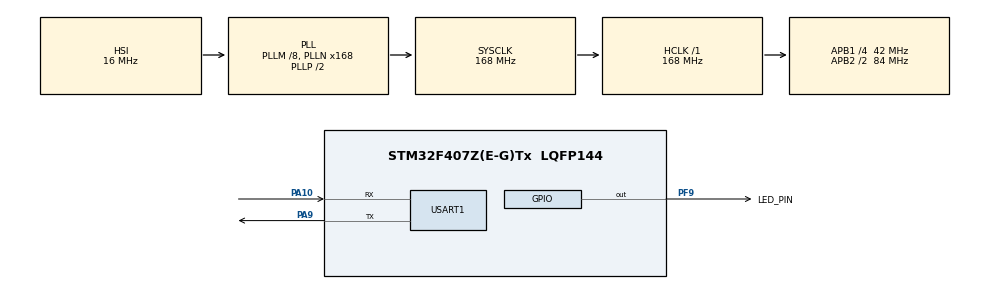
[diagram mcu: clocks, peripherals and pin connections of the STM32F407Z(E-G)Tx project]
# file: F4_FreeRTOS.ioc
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FREERTOS.Mutexes01=myMutex01,Dynamic,NULL,Available
FREERTOS.Tasks01=LCDTask,24,128,StartLCDTask,Default,NULL,Dynamic,NULL,NULL;USARTTask,32,128,StartUSARTTask,Default,NULL,Dynamic,NULL,NULL
Mcu.Family=STM32F4
Mcu.Name=STM32F407Z(E-G)Tx
Mcu.Package=LQFP144
NVIC.PriorityGroup=NVIC_PRIORITYGROUP_4
NVIC.TIM6_DAC_IRQn=true\:15\:0\:false\:false\:true\:false\:false\:true\:true
NVIC.TimeBase=TIM6_DAC_IRQn
NVIC.TimeBaseIP=TIM6
NVIC.USART1_IRQn=true\:5\:0\:false\:false\:true\:true\:true\:true\:true
PA10.Mode=Asynchronous
PA10.Signal=USART1_RX
PA13.Mode=Serial_Wire
PA13.Signal=SYS_JTMS-SWDIO
PA14.Mode=Serial_Wire
PA14.Signal=SYS_JTCK-SWCLK
PA9.Mode=Asynchronous
PA9.Signal=USART1_TX
PF9.GPIO_Label=LED_PIN
PF9.Signal=GPIO_Output
PH0-OSC_IN.Mode=HSE-External-Oscillator
PH0-OSC_IN.Signal=RCC_OSC_IN
PH1-OSC_OUT.Mode=HSE-External-Oscillator
PH1-OSC_OUT.Signal=RCC_OSC_OUT
ProjectManager.HeapSize=0x400
ProjectManager.StackSize=0x1000
ProjectManager.TargetToolchain=CMake
RCC.48MHZClocksFreq_Value=84000000
RCC.AHBFreq_Value=168000000
RCC.APB1CLKDivider=RCC_HCLK_DIV4
RCC.APB1Freq_Value=42000000
RCC.APB1TimFreq_Value=84000000
RCC.APB2CLKDivider=RCC_HCLK_DIV2
RCC.APB2Freq_Value=84000000
RCC.APB2TimFreq_Value=168000000
RCC.CortexFreq_Value=168000000
RCC.HCLKFreq_Value=168000000
RCC.HSE_VALUE=8000000
RCC.HSI_VALUE=16000000
RCC.LSE_VALUE=32768
RCC.PLLM=8
RCC.PLLN=168
RCC.SYSCLKFreq_VALUE=168000000
RCC.SYSCLKSource=RCC_SYSCLKSOURCE_PLLCLK
RCC.VCOOutputFreq_Value=336000000
USART1.VirtualMode=VM_ASYNC
VP_FREERTOS_VS_CMSIS_V2.Mode=CMSIS_V2
VP_SYS_VS_tim6.Mode=TIM6
board=custom

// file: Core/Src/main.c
/* USER CODE BEGIN Header */
/**
  ******************************************************************************
  * @file           : main.c
  * @brief          : Main program body
  ******************************************************************************
  * @attention
  *
  * Copyright (c) 2026 STMicroelectronics.
  * All rights reserved.
  *
  * This software is licensed under terms that can be found in the LICENSE file
  * in the root directory of this software component.
  * If no LICENSE file comes with this software, it is provided AS-IS.
  *
  ******************************************************************************
  */
/* USER CODE END Header */
#include "main.h"
#include "cmsis_os.h"
#include "usart.h"
#include "gpio.h"

void SystemClock_Config(void);
void MX_FREERTOS_Init(void);

int main(void)
{

  /* MCU Configuration--------------------------------------------------------*/

  /* Reset of all peripherals, Initializes the Flash interface and the Systick. */
  HAL_Init();

  /* Configure the system clock */
  SystemClock_Config();

  /* Initialize all configured peripherals */
  MX_GPIO_Init();
  MX_USART1_UART_Init();

  /* Init scheduler */
  osKernelInitialize();  /* Call init function for freertos objects (in cmsis_os2.c) */
  MX_FREERTOS_Init();

  /* Start scheduler */
  osKernelStart();

  /* We should never get here as control is now taken by the scheduler */

  /* Infinite loop */
  while (1)
  {

  }
}

void SystemClock_Config(void)
{
  RCC_OscInitTypeDef RCC_OscInitStruct = {0};
  RCC_ClkInitTypeDef RCC_ClkInitStruct = {0};

  /** Configure the main internal regulator output voltage
  */
  __HAL_RCC_PWR_CLK_ENABLE();
  __HAL_PWR_VOLTAGESCALING_CONFIG(PWR_REGULATOR_VOLTAGE_SCALE1);

  /** Initializes the RCC Oscillators according to the specified parameters
  * in the RCC_OscInitTypeDef structure.
  */
  RCC_OscInitStruct.OscillatorType = RCC_OSCILLATORTYPE_HSI;
  RCC_OscInitStruct.HSIState = RCC_HSI_ON;
  RCC_OscInitStruct.HSICalibrationValue = RCC_HSICALIBRATION_DEFAULT;
  RCC_OscInitStruct.PLL.PLLState = RCC_PLL_ON;
  RCC_OscInitStruct.PLL.PLLSource = RCC_PLLSOURCE_HSI;
  RCC_OscInitStruct.PLL.PLLM = 8;
  RCC_OscInitStruct.PLL.PLLN = 168;
  RCC_OscInitStruct.PLL.PLLP = RCC_PLLP_DIV2;
  RCC_OscInitStruct.PLL.PLLQ = 4;
  if (HAL_RCC_OscConfig(&RCC_OscInitStruct) != HAL_OK)
  {
    Error_Handler();
  }

  /** Initializes the CPU, AHB and APB buses clocks
  */
  RCC_ClkInitStruct.ClockType = RCC_CLOCKTYPE_HCLK|RCC_CLOCKTYPE_SYSCLK
                              |RCC_CLOCKTYPE_PCLK1|RCC_CLOCKTYPE_PCLK2;
  RCC_ClkInitStruct.SYSCLKSource = RCC_SYSCLKSOURCE_PLLCLK;
  RCC_ClkInitStruct.AHBCLKDivider = RCC_SYSCLK_DIV1;
  RCC_ClkInitStruct.APB1CLKDivider = RCC_HCLK_DIV4;
  RCC_ClkInitStruct.APB2CLKDivider = RCC_HCLK_DIV2;

  if (HAL_RCC_ClockConfig(&RCC_ClkInitStruct, FLASH_LATENCY_5) != HAL_OK)
  {
    Error_Handler();
  }
}

void HAL_TIM_PeriodElapsedCallback(TIM_HandleTypeDef *htim)
{
  if (htim->Instance == TIM6)
  {
    HAL_IncTick();
  }
}

void Error_Handler(void)
{
  __disable_irq();
  while (1)
  {
  }
}

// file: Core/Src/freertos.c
/* USER CODE BEGIN Header */
/**
 ******************************************************************************
 * File Name          : freertos.c
 * Description        : Code for freertos applications
 ******************************************************************************
 * @attention
 *
 * Copyright (c) 2026 STMicroelectronics.
 * All rights reserved.
 *
 * This software is licensed under terms that can be found in the LICENSE file
 * in the root directory of this software component.
 * If no LICENSE file comes with this software, it is provided AS-IS.
 *
 ******************************************************************************
 */
/* USER CODE END Header */

#include "FreeRTOS.h"
#include "task.h"
#include "main.h"
#include "cmsis_os.h"

/* USER CODE BEGIN Includes */
#include "gpio.h"
#include "stdarg.h"
#include "stdio.h"
#include "string.h"
#include "usart.h"
/* USER CODE END Includes */

/* USER CODE BEGIN PD */
#define LED_TOGGLE_PERIOD       100  // 100ms (0.1秒)
#define USART_BUFFER_SIZE       64
#define HELLO_WORLD_INTERVAL    500  // 500ms发送一次hello world
/* USER CODE END PD */

/* USER CODE BEGIN Variables */
volatile uint8_t led_state = 0;

/* USER CODE END Variables */
/* Definitions for LCDTask */
osThreadId_t LCDTaskHandle;
const osThreadAttr_t LCDTask_attributes = {
  .name = "LCDTask",
  .stack_size = 128 * 4,
  .priority = (osPriority_t) osPriorityNormal,
};
/* Definitions for USARTTask */
osThreadId_t USARTTaskHandle;
const osThreadAttr_t USARTTask_attributes = {
  .name = "USARTTask",
  .stack_size = 128 * 4,
  .priority = (osPriority_t) osPriorityAboveNormal,
};
/* Definitions for myMutex01 */
osMutexId_t myMutex01Handle;
const osMutexAttr_t myMutex01_attributes = {
  .name = "myMutex01"
};

void StartLCDTask(void *argument);
void StartUSARTTask(void *argument);

void MX_FREERTOS_Init(void); /* (MISRA C 2004 rule 8.1) */

void MX_FREERTOS_Init(void) {
  /* Create the mutex(es) */
  /* creation of myMutex01 */
  myMutex01Handle = osMutexNew(&myMutex01_attributes);

  /* Create the thread(s) */
  /* creation of LCDTask */
  LCDTaskHandle = osThreadNew(StartLCDTask, NULL, &LCDTask_attributes);

  /* creation of USARTTask */
  USARTTaskHandle = osThreadNew(StartUSARTTask, NULL, &USARTTask_attributes);

}

void StartLCDTask(void *argument)
{
  /* USER CODE BEGIN StartLCDTask */
  uint32_t last_toggle_time = 0;
  uint32_t current_time = 0;

  // 使用互斥锁保护UART访问
  if (osMutexAcquire(myMutex01Handle, osWaitForever) == osOK) {
    HAL_UART_Transmit(&huart1, (uint8_t*)"LED Control Task Started\r\n", 26, HAL_MAX_DELAY);
    osMutexRelease(myMutex01Handle);
  }

  /* Infinite loop */
  for(;;)
  {
    current_time = HAL_GetTick();

    // 0.1秒自动闪烁
    if (current_time - last_toggle_time >= LED_TOGGLE_PERIOD) {
      HAL_GPIO_TogglePin(LED_PIN_GPIO_Port, LED_PIN_Pin);
      led_state = !led_state;
      last_toggle_time = current_time;

      // 安全的UART打印
      if (osMutexAcquire(myMutex01Handle, osWaitForever) == osOK) {
        char msg[30];
        snprintf(msg, sizeof(msg), "LED Toggled - State: %d\r\n", led_state);
        HAL_UART_Transmit(&huart1, (uint8_t*)msg, strlen(msg), HAL_MAX_DELAY);
        osMutexRelease(myMutex01Handle);
      }
    }

    osDelay(10); // 10ms延迟，降低CPU占用
  }
  /* USER CODE END StartLCDTask */
}

void StartUSARTTask(void *argument)
{
  /* USER CODE BEGIN StartUSARTTask */
  uint32_t last_hello_time = 0;
  uint32_t current_time = 0;

  // 使用互斥锁保护初始化消息
  if (osMutexAcquire(myMutex01Handle, osWaitForever) == osOK) {
    HAL_UART_Transmit(&huart1, (uint8_t*)"USART Communication Task Started!\r\n", 35, HAL_MAX_DELAY);
    osMutexRelease(myMutex01Handle);
  }

  /* Infinite loop */
  for(;;)
  {
    current_time = HAL_GetTick();

    // 每500ms发送一次hello world
    if (current_time - last_hello_time >= HELLO_WORLD_INTERVAL) {
      if (osMutexAcquire(myMutex01Handle, osWaitForever) == osOK) {
        HAL_UART_Transmit(&huart1, (uint8_t*)"hello,world!\r\n", 14, HAL_MAX_DELAY);
        osMutexRelease(myMutex01Handle);
      }
      last_hello_time = current_time;
    }

    osDelay(100); // 100ms延迟，平衡性能和响应性
  }
  /* USER CODE END StartUSARTTask */
}
